AUTOSAR XML (schema 4-0-3)
standard types defined: Boolean, UInt16, UInt32
package /AUTOSAR_Platform/DataConstrs
  range DC_Boolean: raw 0..1
  range DC_UInt16: raw 0..65535
package /PATAC/MSM/ComponentTypes
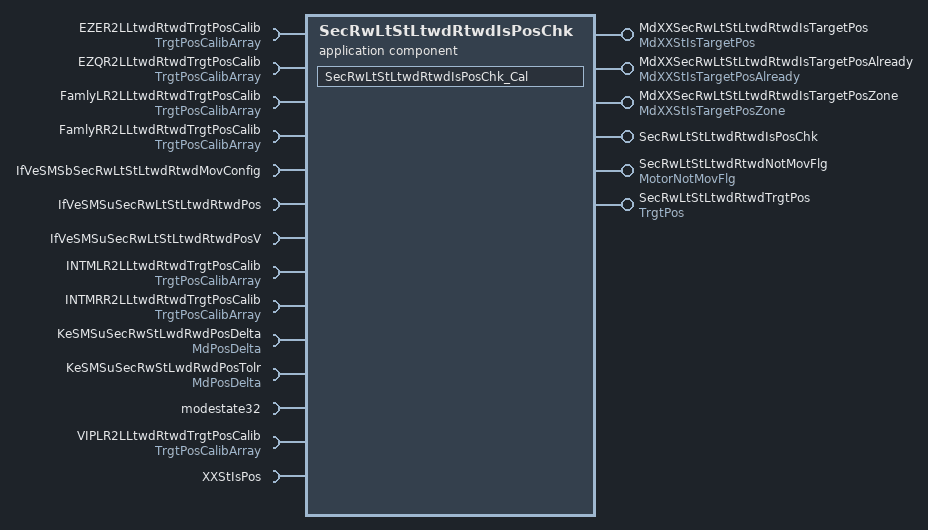
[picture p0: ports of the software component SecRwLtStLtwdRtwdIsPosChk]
  application sw component type SecRwLtStLtwdRtwdIsPosChk
    6 x provide port:
      MdXXSecRwLtStLtwdRtwdIsTargetPos: nonqueued-sender-com-spec=data-element=MdXXStIsTargetPos/Val, provided-interface=MdXXStIsTargetPos
      MdXXSecRwLtStLtwdRtwdIsTargetPosAlready: nonqueued-sender-com-spec=data-element=MdXXStIsTargetPosAlready/Val, provided-interface=MdXXStIsTargetPosAlready
      MdXXSecRwLtStLtwdRtwdIsTargetPosZone: nonqueued-sender-com-spec=data-element=MdXXStIsTargetPosZone/Val, provided-interface=MdXXStIsTargetPosZone
      SecRwLtStLtwdRtwdIsPosChk: server-com-spec{operation=Cal, queue-length=1}, provided-interface=SecRwLtStLtwdRtwdIsPosChk
      SecRwLtStLtwdRtwdNotMovFlg: nonqueued-sender-com-spec{data-element=MotorNotMovFlg/Val, init-value=0}, provided-interface=MotorNotMovFlg
      SecRwLtStLtwdRtwdTrgtPos: nonqueued-sender-com-spec{data-element=TrgtPos/Val, init-value=4095}, provided-interface=TrgtPos
    14 x require port:
      EZER2LLtwdRtwdTrgtPosCalib: nonqueued-receiver-com-spec{data-element=TrgtPosArray, filter=data-filter-type=ALWAYS, init-value=[4095, 4095, 4095]}, required-interface=TrgtPosCalibArray
      EZQR2LLtwdRtwdTrgtPosCalib: nonqueued-receiver-com-spec{data-element=TrgtPosArray, filter=data-filter-type=ALWAYS, init-value=[4095, 4095, 4095]}, required-interface=TrgtPosCalibArray
      FamlyLR2LLtwdRtwdTrgtPosCalib: nonqueued-receiver-com-spec{data-element=TrgtPosArray, filter=data-filter-type=ALWAYS, init-value=[4095, 4095, 4095]}, required-interface=TrgtPosCalibArray
      FamlyRR2LLtwdRtwdTrgtPosCalib: nonqueued-receiver-com-spec{data-element=TrgtPosArray, filter=data-filter-type=ALWAYS, init-value=[4095, 4095, 4095]}, required-interface=TrgtPosCalibArray
      IfVeSMSbSecRwLtStLtwdRtwdMovConfig: nonqueued-receiver-com-spec{data-element=IfVeSMSbSecRwLtStLtwdRtwdMovConfig/Val, filter=data-filter-type=ALWAYS, init-value=0}, required-interface=IfVeSMSbSecRwLtStLtwdRtwdMovConfig
      IfVeSMSuSecRwLtStLtwdRtwdPos: nonqueued-receiver-com-spec{data-element=IfVeSMSuSecRwLtStLtwdRtwdPos/Val, filter=data-filter-type=ALWAYS, init-value=0}, required-interface=IfVeSMSuSecRwLtStLtwdRtwdPos
      IfVeSMSuSecRwLtStLtwdRtwdPosV: nonqueued-receiver-com-spec{data-element=IfVeSMSuSecRwLtStLtwdRtwdPosV/Val, filter=data-filter-type=ALWAYS, init-value=0}, required-interface=IfVeSMSuSecRwLtStLtwdRtwdPosV
      INTMLR2LLtwdRtwdTrgtPosCalib: nonqueued-receiver-com-spec{data-element=TrgtPosArray, filter=data-filter-type=ALWAYS, init-value=[4095, 4095, 4095]}, required-interface=TrgtPosCalibArray
      INTMRR2LLtwdRtwdTrgtPosCalib: nonqueued-receiver-com-spec{data-element=TrgtPosArray, filter=data-filter-type=ALWAYS, init-value=[4095, 4095, 4095]}, required-interface=TrgtPosCalibArray
      KeSMSuSecRwStLwdRwdPosDelta: parameter-require-com-spec{init-value=150, parameter=Val}, required-interface=MdPosDelta
      KeSMSuSecRwStLwdRwdPosTolr: parameter-require-com-spec{init-value=150, parameter=Val}, required-interface=MdPosDelta
      modestate32: nonqueued-receiver-com-spec{data-element=modestate32/Val, filter=data-filter-type=ALWAYS, init-value=0}, required-interface=modestate32
      VIPLR2LLtwdRtwdTrgtPosCalib: nonqueued-receiver-com-spec{data-element=TrgtPosArray, filter=data-filter-type=ALWAYS, init-value=[4095, 4095, 4095]}, required-interface=TrgtPosCalibArray
      XXStIsPos: client-com-spec=Get, required-interface=XXStIsPos
    behavior SecRwLtStLtwdRtwdIsPosChk_InternalBehavior
      operation invoked event OIT_SecRwLtStLtwdRtwdIsPosChk_Cal_SecRwLtStLtwdRtwdIsPosChk_Cal: start-on-event=SecRwLtStLtwdRtwdIsPosChk_Cal, operation=SecRwLtStLtwdRtwdIsPosChk.Cal
      runnable SecRwLtStLtwdRtwdIsPosChk_Cal
        data-receive-point-by-arguments:
          11 x access:
            REC_EZER2LLtwdRtwdTrgtPosCalib_TrgtPosArray: accessed-variable=EZER2LLtwdRtwdTrgtPosCalib.TrgtPosArray
            REC_EZQR2LLtwdRtwdTrgtPosCalib_TrgtPosArray: accessed-variable=EZQR2LLtwdRtwdTrgtPosCalib.TrgtPosArray
            REC_FamlyLR2LLtwdRtwdTrgtPosCalib_TrgtPosArray: accessed-variable=FamlyLR2LLtwdRtwdTrgtPosCalib.TrgtPosArray
            REC_FamlyRR2LLtwdRtwdTrgtPosCalib_TrgtPosArray: accessed-variable=FamlyRR2LLtwdRtwdTrgtPosCalib.TrgtPosArray
            REC_IfVeSMSbSecRwLtStLtwdRtwdMovConfig_Val: accessed-variable=IfVeSMSbSecRwLtStLtwdRtwdMovConfig.Val
            REC_IfVeSMSuSecRwLtStLtwdRtwdPos_Val: accessed-variable=IfVeSMSuSecRwLtStLtwdRtwdPos.Val
            REC_IfVeSMSuSecRwLtStLtwdRtwdPosV_Val: accessed-variable=IfVeSMSuSecRwLtStLtwdRtwdPosV.Val
            REC_INTMLR2LLtwdRtwdTrgtPosCalib_TrgtPosArray: accessed-variable=INTMLR2LLtwdRtwdTrgtPosCalib.TrgtPosArray
            REC_INTMRR2LLtwdRtwdTrgtPosCalib_TrgtPosArray: accessed-variable=INTMRR2LLtwdRtwdTrgtPosCalib.TrgtPosArray
            REC_modestate32_Val: accessed-variable=modestate32.Val
            REC_VIPLR2LLtwdRtwdTrgtPosCalib_TrgtPosArray: accessed-variable=VIPLR2LLtwdRtwdTrgtPosCalib.TrgtPosArray
        data-send-points:
          5 x access:
            SEND_MdXXSecRwLtStLtwdRtwdIsTargetPos_Val: accessed-variable=MdXXSecRwLtStLtwdRtwdIsTargetPos.Val
            SEND_MdXXSecRwLtStLtwdRtwdIsTargetPosAlready_Val: accessed-variable=MdXXSecRwLtStLtwdRtwdIsTargetPosAlready.Val
            SEND_MdXXSecRwLtStLtwdRtwdIsTargetPosZone_Val: accessed-variable=MdXXSecRwLtStLtwdRtwdIsTargetPosZone.Val
            SEND_SecRwLtStLtwdRtwdNotMovFlg_Val: accessed-variable=SecRwLtStLtwdRtwdNotMovFlg.Val
            SEND_SecRwLtStLtwdRtwdTrgtPos_Val: accessed-variable=SecRwLtStLtwdRtwdTrgtPos.Val
        parameter access PA_KeSMSuSecRwStLwdRwdPosDelta_Val: accessed-parameter=KeSMSuSecRwStLwdRwdPosDelta.Val
        parameter access PA_KeSMSuSecRwStLwdRwdPosTolr_Val: accessed-parameter=KeSMSuSecRwStLwdRwdPosTolr.Val
        sync call SC_XXStIsPos_Get: operation=XXStIsPos.Get, timeout=0
  swc implementation SecRwLtStLtwdRtwdIsPosChk_Implementation: behavior=SecRwLtStLtwdRtwdIsPosChk_InternalBehavior
    code-descriptors:
      code Default: artifact-descriptors=autosar-engineering-object={short-label=Default, category=SWSRC}
package /PATAC/MSM/ModeAdjust/CalPortInterface
  parameter interface MdPosDelta
    parameter data prototype Val: sw-calibration-access=READ-WRITE, type=UInt16
package /PATAC/MSM/ModeAdjust/DataType
  impl type TrgtPosCalibArray: category=ARRAY, sw-calibration-access=READ-ONLY, type-emitter=RTE  # 0:pos 1:max 2:min
    element Element: array-size=3, array-size-semantics=FIXED-SIZE, implementation-data-type=UInt16, invalid-value=0
package /PATAC/MSM/ModeAdjust/Interfaces
  sender receiver interface IfVeSMSuSecRwLtStLtwdRtwdPosV: invalidation-policy{data-element=IfVeSMSuSecRwLtStLtwdRtwdPosV/Val, handle-invalid=DONT-INVALIDATE}
    data Val: type=Implementation/Boolean
package /PATAC/MSM/ModeAdjust/PortInterface
  client server interface SecRwLtStLtwdRtwdIsPosChk
    operation Cal
  client server interface XXStIsPos
    operation Get
      8 x arg, all with server-argument-impl-policy=USE-ARGUMENT-TYPE:
        PosV: type=DataTypes/Boolean, direction=IN
        Pos: type=UInt16, direction=IN
        CalibArray: type=TrgtPosCalibArray, direction=IN
        Delta: type=UInt16, direction=IN
        Tolr: type=UInt16, direction=IN
        IsPos: type=DataTypes/Boolean, direction=OUT
        IsPosZone: type=DataTypes/Boolean, direction=OUT
        IsPosAlready: type=DataTypes/Boolean, direction=OUT
  6 x sender receiver interface:
    MdXXStIsTargetPos: invalidation-policy{data-element=MdXXStIsTargetPos/Val, handle-invalid=DONT-INVALIDATE}
      data Val: type=UInt32
    MdXXStIsTargetPosAlready: invalidation-policy{data-element=MdXXStIsTargetPosAlready/Val, handle-invalid=DONT-INVALIDATE}
      data Val: type=UInt32
    MdXXStIsTargetPosZone: invalidation-policy{data-element=MdXXStIsTargetPosZone/Val, handle-invalid=DONT-INVALIDATE}
      data Val: type=UInt32
    modestate32: invalidation-policy{data-element=modestate32/Val, handle-invalid=DONT-INVALIDATE}
      data Val: type=UInt32
    MotorNotMovFlg: invalidation-policy{data-element=MotorNotMovFlg/Val, handle-invalid=DONT-INVALIDATE}
      data Val: type=Implementation/Boolean
    TrgtPosCalibArray: invalidation-policy{data-element=TrgtPosArray, handle-invalid=DONT-INVALIDATE}
      data TrgtPosArray: type=TrgtPosCalibArray  # 0:Pos 1:Max 2:Min
package /PATAC/MSM/PortInterfaces
  sender receiver interface IfVeSMSbSecRwLtStLtwdRtwdMovConfig: invalidation-policy{data-element=IfVeSMSbSecRwLtStLtwdRtwdMovConfig/Val, handle-invalid=DONT-INVALIDATE}
    data Val: type=Implementation/Boolean
  sender receiver interface IfVeSMSuSecRwLtStLtwdRtwdPos: invalidation-policy{data-element=IfVeSMSuSecRwLtStLtwdRtwdPos/Val, handle-invalid=DONT-INVALIDATE}
    data Val: type=UInt16
  sender receiver interface TrgtPos: invalidation-policy{data-element=TrgtPos/Val, handle-invalid=DONT-INVALIDATE}
    data Val: type=UInt16
